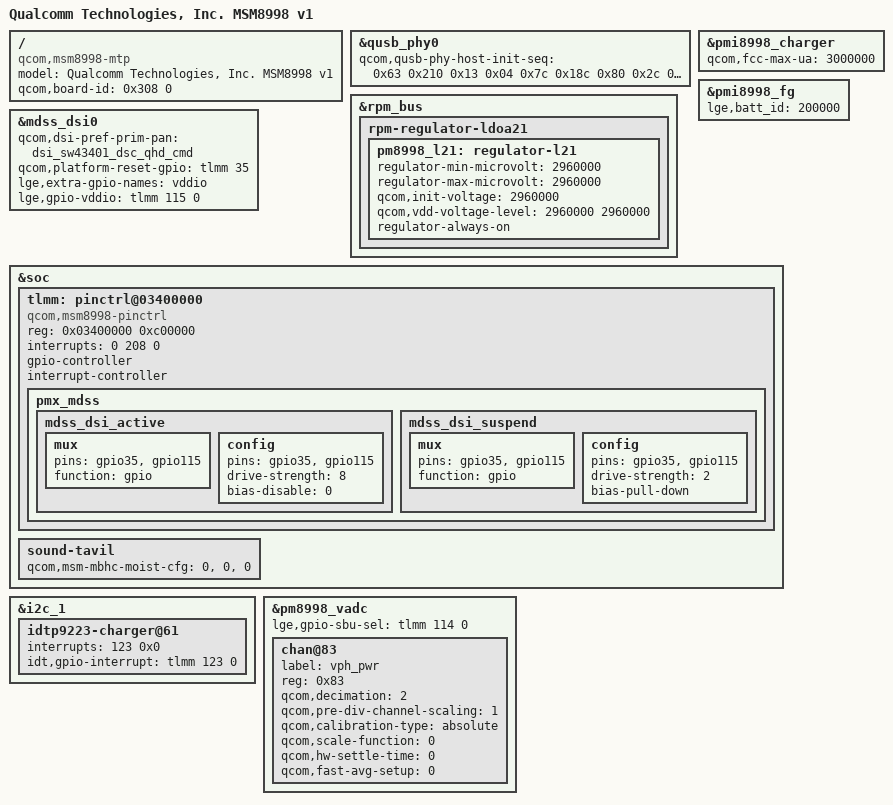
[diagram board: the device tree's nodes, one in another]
/* Copyright (c) 2016, The Linux Foundation. All rights reserved.
 *
 * This program is free software; you can redistribute it and/or modify
 * it under the terms of the GNU General Public License version 2 and
 * only version 2 as published by the Free Software Foundation.
 *
 * This program is distributed in the hope that it will be useful,
 * but WITHOUT ANY WARRANTY; without even the implied warranty of
 * MERCHANTABILITY or FITNESS FOR A PARTICULAR PURPOSE.  See the
 * GNU General Public License for more details.
 */


/dts-v1/;

#include "../../../qcom/msm8998.dtsi"
#include "msm8998-joan_kr.dtsi"

/ {
	model = "Qualcomm Technologies, Inc. MSM8998 v1";
	compatible = "qcom,msm8998-mtp", "qcom,msm8998", "qcom,mtp";
	qcom,board-id = <0x308 0>;
};

&qusb_phy0 {
	qcom,qusb-phy-host-init-seq =
			/* value reg_offsets> */
				<0x63 0x210
				0x13 0x04
				0x7c 0x18c
				0x80 0x2c
				0x0a 0x184
				0x8c 0x21c
				0x05 0x23c
				0x03 0x240
				0xff 0x218
				0x62 0x210>;
};

&pmi8998_charger {
	qcom,fcc-max-ua = <3000000>;
};

&pmi8998_fg {
       lge,batt_id = <200000>;
};

&rpm_bus {
	rpm-regulator-ldoa21 {
		status = "okay";
pm8998_l21: regulator-l21 {
				regulator-min-microvolt = <2960000>;
				regulator-max-microvolt = <2960000>;
				qcom,init-voltage = <2960000>;
				qcom,vdd-voltage-level = <2960000 2960000>;
				regulator-always-on;
				status = "okay";
			};
	};
};

&mdss_dsi0 {
	qcom,dsi-pref-prim-pan = <&dsi_sw43401_dsc_qhd_cmd>;
	qcom,platform-reset-gpio = <&tlmm 35 0>;
	lge,extra-gpio-names = "vddio";
	lge,gpio-vddio = <&tlmm 115 0>;
};


&soc {
	tlmm: pinctrl@03400000 {
		compatible = "qcom,msm8998-pinctrl";
		reg = <0x03400000 0xc00000>;
		interrupts = <0 208 0>;
		gpio-controller;
		#gpio-cells = <2>;
		interrupt-controller;
		#interrupt-cells = <2>;

		pmx_mdss: pmx_mdss {
			mdss_dsi_active: mdss_dsi_active {
				mux {
					pins = "gpio35", "gpio115";
					function = "gpio";
				};

				config {
					pins = "gpio35", "gpio115";
					drive-strength = <8>; /* 8 mA */
					bias-disable = <0>; /* no pull */
				};
			};
			mdss_dsi_suspend: mdss_dsi_suspend {
				mux {
					pins = "gpio35", "gpio115";
					function = "gpio";
				};

				config {
					pins = "gpio35", "gpio115";
					drive-strength = <2>; /* 2 mA */
					bias-pull-down; /* pull down */
				};
			};
		};
	};
	sound-tavil {
		qcom,msm-mbhc-moist-cfg = <0>, <0>, <0>;
	};
};

&i2c_1 { /* BLSP1 QUP1 */
	idtp9223-charger@61 {               /* Slave driver and slave Address */
		interrupts = <123 0x0>;         /* GPIO # will be converted to gpio_activated # */
		idt,gpio-interrupt = <&tlmm 123 0>;
	};
};

&pm8998_vadc {
	lge,gpio-sbu-sel = <&tlmm 114 0>;
	chan@83 {
		label = "vph_pwr";
		reg = <0x83>;
		qcom,decimation = <2>;
		qcom,pre-div-channel-scaling = <1>;
		qcom,calibration-type = "absolute";
		qcom,scale-function = <0>;
		qcom,hw-settle-time = <0>;
		qcom,fast-avg-setup = <0>;
	};
};
